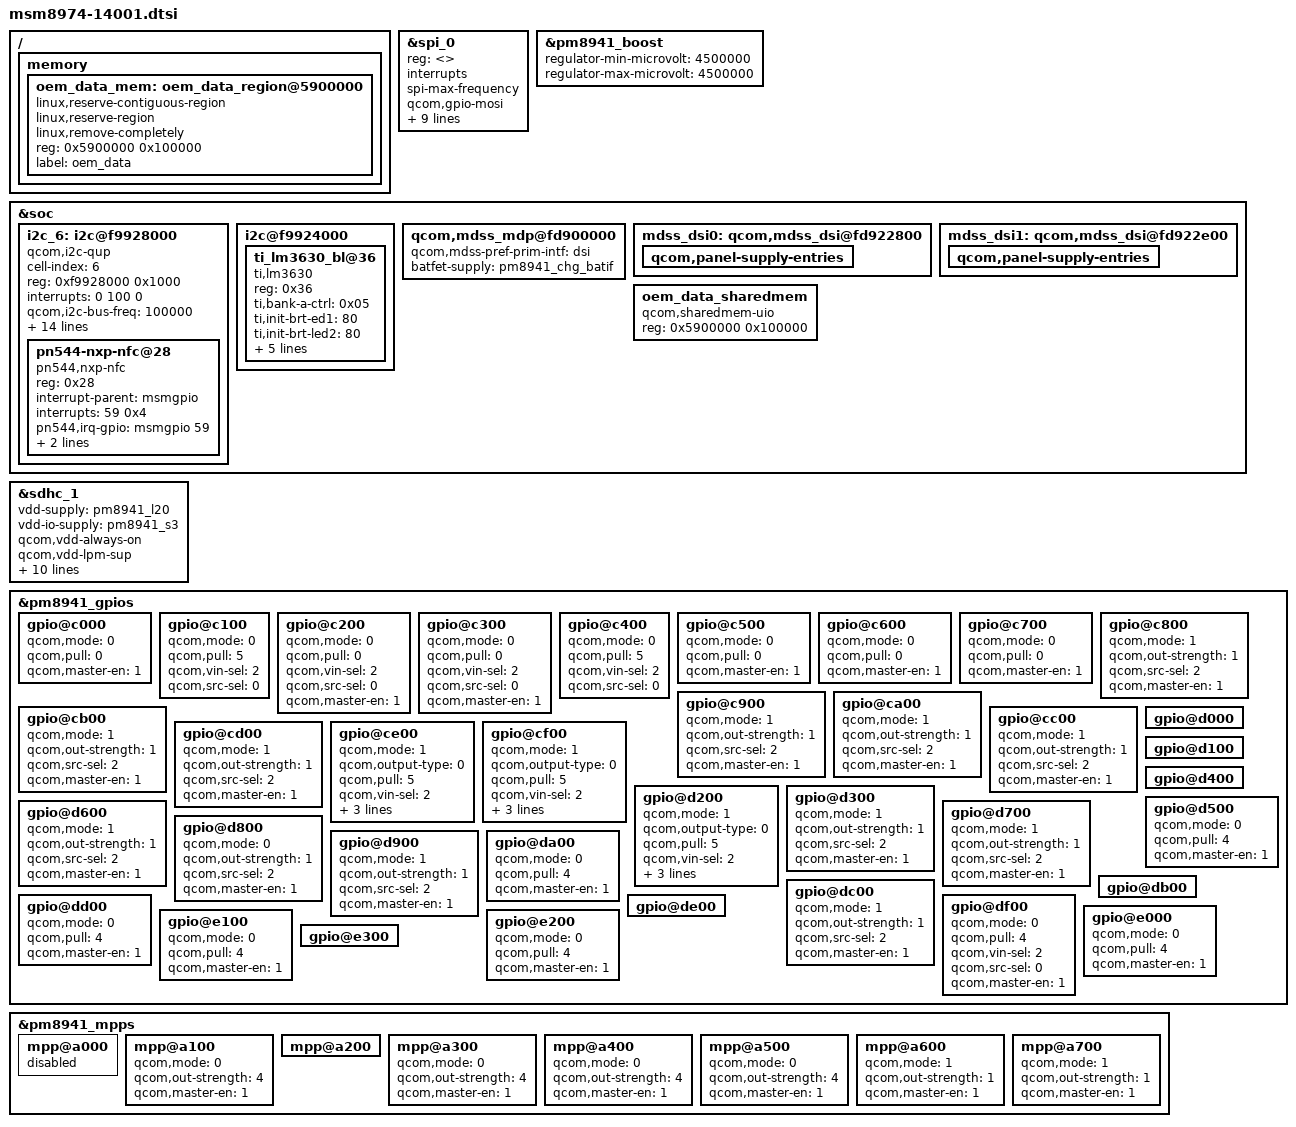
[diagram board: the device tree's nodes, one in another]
/* Copyright (c) 2012-2013, The Linux Foundation. All rights reserved.
 *
 * This program is free software; you can redistribute it and/or modify
 * it under the terms of the GNU General Public License version 2 and
 * only version 2 as published by the Free Software Foundation.
 *
 * This program is distributed in the hope that it will be useful,
 * but WITHOUT ANY WARRANTY; without even the implied warranty of
 * MERCHANTABILITY or FITNESS FOR A PARTICULAR PURPOSE.  See the
 * GNU General Public License for more details.
 */

#include "dsi-panel-jdi-1080p-cmd.dtsi"
#include "../../qcom/msm8974-leds.dtsi"
#include "msm8974-14001-camera.dtsi"
#include "msm8974-oppo-input.dtsi"
#include "msm8974-oppo-pm.dtsi"
#include "msm8974-oppo-regulator.dtsi"

/ {
	memory {
		oem_data_mem: oem_data_region@5900000 {
			linux,reserve-contiguous-region;
			linux,reserve-region;
			linux,remove-completely;
			reg = <0x5900000 0x100000>;
			label = "oem_data";
		};
	};
};

&spi_0 {
	compatible;
	reg-names;
	reg = <>;
	interrupt-names;
	interrupts;
	spi-max-frequency;
	qcom,gpio-mosi;
	qcom,gpio-miso;
	qcom,gpio-clk;
	qcom,gpio-cs0;
	qcom,infinite-mode;
	qcom,use-bam;
	qcom,ver-reg-exists;
	qcom,bam-consumer-pipe-index;
	qcom,bam-producer-pipe-index;
	qcom,master-id;
};

&pm8941_boost {
	regulator-min-microvolt = <4500000>;
	regulator-max-microvolt = <4500000>;
};

&soc {
	i2c_6: i2c@f9928000 {
		cell-index = <6>;
		compatible = "qcom,i2c-qup";
		reg = <0xf9928000 0x1000>;
		#address-cells = <1>;
		#size-cells = <0>;
		reg-names = "qup_phys_addr";
		interrupts = <0 100 0>;
		interrupt-names = "qup_err_intr";
		qcom,i2c-bus-freq = <100000>;
		qcom,i2c-src-freq = <19200000>;
		qcom,scl-gpio = <&msmgpio 30 0>;
		qcom,sda-gpio = <&msmgpio 29 0>;
		qcom,active-only;
		qcom,master-id = <86>;

		qcom,gpio-mosi = <&msmgpio 0 0>;
		qcom,gpio-miso = <&msmgpio 1 0>;
		qcom,gpio-clk  = <&msmgpio 3 0>;
		qcom,gpio-cs2  = <&msmgpio 9 0>;

		qcom,infinite-mode = <0>;
		qcom,use-bam;
		qcom,ver-reg-exists;
		qcom,bam-consumer-pipe-index = <12>;
		qcom,bam-producer-pipe-index = <13>;
		qcom,master-id = <86>;

		pn544-nxp-nfc@28 {
			compatible = "pn544,nxp-nfc";
			reg = <0x28>;
			interrupt-parent = <&msmgpio>;
			interrupts = <59 0x4>;
			pn544,irq-gpio = <&msmgpio 59 0x00>;
			pn544,enable-gpio = <&msmgpio 13 0x00>;
			pn544,update-gpio = <&msmgpio 12 0x00>;
		};
	};

	i2c@f9924000 {
		ti_lm3630_bl@36 {
			compatible = "ti,lm3630";
			reg = <0x36>;
			ti,bank-a-ctrl = <0x05>;
			ti,init-brt-ed1 = <80>;
			ti,init-brt-led2 = <80>;
			ti,max-brt-led1 = <255>;
			ti,max-brt-led2 = <255>;
			ti,pwm-active = <0>;
			ti,pwm-ctrl = <0>;
			ti,pwm-period = <255>;
		};
	};

	qcom,mdss_mdp@fd900000 {
		qcom,mdss-pref-prim-intf = "dsi";
		batfet-supply = <&pm8941_chg_batif>;
	};

	mdss_dsi0: qcom,mdss_dsi@fd922800 {
		qcom,panel-supply-entries {
			/delete-property/ qcom,panel-supply-entry@0;
		};
	};

	mdss_dsi1: qcom,mdss_dsi@fd922e00 {
		qcom,panel-supply-entries {
			/delete-property/ qcom,panel-supply-entry@0;
		};
	};

	oem_data_sharedmem {
		compatible = "qcom,sharedmem-uio";
		reg = <0x5900000 0x100000>;
		reg-names = "oem_data";
	};
};

&sdhc_1 {
	vdd-supply = <&pm8941_l20>;
	vdd-io-supply = <&pm8941_s3>;

	qcom,vdd-always-on;
	qcom,vdd-lpm-sup;
	qcom,vdd-voltage-level = <2950000 2950000>;
	qcom,vdd-current-level = <800 500000>;

	qcom,vdd-io-always-on;
	qcom,vdd-io-voltage-level = <1800000 1800000>;
	qcom,vdd-io-current-level = <250 154000>;

	pinctrl-names = "active", "sleep";
	pinctrl-0 = <&sdc1_clk_on &sdc1_cmd_on &sdc1_data_on>;
	pinctrl-1 = <&sdc1_clk_off &sdc1_cmd_off &sdc1_data_off>;

	qcom,nonremovable;
	status = "ok";
};

&pm8941_gpios {
	gpio@c000 { /* GPIO 1 */
		qcom,mode = <0>;        /* QPNP_PIN_MODE_DIG_IN */
		qcom,pull = <0>;        /* QPNP_PIN_PULL_UP_30  */
		qcom,master-en = <1>;
	};

	gpio@c100 { /* GPIO 2 */
		qcom,mode = <0>;        /* QPNP_PIN_MODE_DIG_IN */
		qcom,pull = <5>;        /* QPNP_PIN_PULL_UP_30  */
		qcom,vin-sel = <2>;
		qcom,src-sel = <0>;
	};

	gpio@c200 { /* GPIO 3 */
		qcom,mode = <0>;        /* QPNP_PIN_MODE_DIG_IN */
		qcom,pull = <0>;        /* QPNP_PIN_PULL_UP_30  */
		qcom,vin-sel = <2>;
		qcom,src-sel = <0>;	/* QPNP_PIN_SEL_FUNC_CONSTANT */
		qcom,master-en = <1>;
	};

	gpio@c300 { /* GPIO 4 */
		qcom,mode = <0>;        /* QPNP_PIN_MODE_DIG_IN */
		qcom,pull = <0>;        /* QPNP_PIN_PULL_UP_30  */
		qcom,vin-sel = <2>;     /* QPNP_PIN_VIN2  */
		qcom,src-sel = <0>;	/* QPNP_PIN_SEL_FUNC_CONSTANT */
		qcom,master-en = <1>;
	};

	gpio@c400 { /* GPIO 5 */
		qcom,mode = <0>;        /* QPNP_PIN_MODE_DIG_IN */
		qcom,pull = <5>;        /* QPNP_PIN_PULL_UP_30  */
		qcom,vin-sel = <2>;     /* QPNP_PIN_VIN2  */
		qcom,src-sel = <0>;	/* QPNP_PIN_SEL_FUNC_CONSTANT */
	};

	gpio@c500 { /* GPIO 6 */
		qcom,mode = <0>;        /* QPNP_PIN_MODE_DIG_IN */
		qcom,pull = <0>;        /* QPNP_PIN_PULL_UP_30  */
		qcom,master-en = <1>;
	};

	gpio@c600 { /* GPIO 7 */
		qcom,mode = <0>;        /* QPNP_PIN_MODE_DIG_IN */
		qcom,pull = <0>;        /* QPNP_PIN_PULL_UP_30  */
		qcom,master-en = <1>;
	};

	gpio@c700 { /* GPIO 8 */
		qcom,mode = <0>;        /* QPNP_PIN_MODE_DIG_IN */
		qcom,pull = <0>;        /* QPNP_PIN_PULL_UP_30  */
		qcom,master-en = <1>;
	};

	gpio@c800 { /* GPIO 9 */
		qcom,mode = <1>;          /* QPNP_PIN_MODE_DIG_OUT */
		qcom,out-strength = <1>;  /* QPNP_PIN_OUT_STRENGTH_LOW */
		qcom,src-sel = <2>;       /* QPNP_PIN_SEL_FUNC_1  */
		qcom,master-en = <1>;
	};

	gpio@c900 { /* GPIO 10 */
		qcom,mode = <1>;          /* QPNP_PIN_MODE_DIG_OUT */
		qcom,out-strength = <1>;  /* QPNP_PIN_OUT_STRENGTH_LOW */
		qcom,src-sel = <2>;       /* QPNP_PIN_SEL_FUNC_1  */
		qcom,master-en = <1>;
	};

	gpio@ca00 { /* GPIO 11 */
		qcom,mode = <1>;          /* QPNP_PIN_MODE_DIG_OUT */
		qcom,out-strength = <1>;  /* QPNP_PIN_OUT_STRENGTH_LOW */
		qcom,src-sel = <2>;       /* QPNP_PIN_SEL_FUNC_1  */
		qcom,master-en = <1>;
	};

	gpio@cb00 { /* GPIO 12 */
		qcom,mode = <1>;          /* QPNP_PIN_MODE_DIG_OUT */
		qcom,out-strength = <1>;  /* QPNP_PIN_OUT_STRENGTH_LOW */
		qcom,src-sel = <2>;       /* QPNP_PIN_SEL_FUNC_1  */
		qcom,master-en = <1>;
	};

	gpio@cc00 { /* GPIO 13 */
		qcom,mode = <1>;          /* QPNP_PIN_MODE_DIG_OUT */
		qcom,out-strength = <1>;  /* QPNP_PIN_OUT_STRENGTH_LOW */
		qcom,src-sel = <2>;       /* QPNP_PIN_SEL_FUNC_1  */
		qcom,master-en = <1>;
	};

	gpio@cd00 { /* GPIO 14 */
		qcom,mode = <1>;          /* QPNP_PIN_MODE_DIG_OUT */
		qcom,out-strength = <1>;  /* QPNP_PIN_OUT_STRENGTH_LOW */
		qcom,src-sel = <2>;       /* QPNP_PIN_SEL_FUNC_1  */
		qcom,master-en = <1>;
	};

	gpio@ce00 { /* GPIO 15 */
		qcom,mode = <1>;
		qcom,output-type = <0>;
		qcom,pull = <5>;
		qcom,vin-sel = <2>;
		qcom,out-strength = <1>;
		qcom,src-sel = <2>;
		qcom,master-en = <1>;
	};

	gpio@cf00 { /* GPIO 16 */
		qcom,mode = <1>;
		qcom,output-type = <0>;
		qcom,pull = <5>;
		qcom,vin-sel = <2>;
		qcom,out-strength = <1>;
		qcom,src-sel = <2>;       /* QPNP_PIN_SEL_FUNC_2  */
		qcom,master-en = <1>;
	};

	gpio@d000 { /* GPIO 17 */
	};

	gpio@d100 { /* GPIO 18 */
	};

	gpio@d200 { /* GPIO 19 */
		qcom,mode = <1>;		/* QPNP_PIN_MODE_DIG_OUT */
		qcom,output-type = <0>;		/* QPNP_PIN_OUT_BUF_CMOS */
		qcom,pull = <5>;		/* QPNP_PIN_PULL_NO */
		qcom,vin-sel = <2>;		/* QPNP_PIN_VIN2 */
		qcom,out-strength = <1>;	/* QPNP_PIN_OUT_STRENGTH_LOW */
		qcom,src-sel = <0>;		/* QPNP_PIN_SEL_FUNC_CONSTANT */
		qcom,master-en = <1>;
	};

	gpio@d300 { /* GPIO 20 */
		qcom,mode = <1>;          /* QPNP_PIN_MODE_DIG_OUT */
		qcom,out-strength = <1>;  /* QPNP_PIN_OUT_STRENGTH_LOW */
		qcom,src-sel = <2>;       /* QPNP_PIN_SEL_FUNC_1  */
		qcom,master-en = <1>;
	};

	gpio@d400 { /* GPIO 21 */
	};

	gpio@d500 { /* GPIO 22 */
		qcom,mode = <0>;        /* QPNP_PIN_MODE_DIG_IN */
		qcom,pull = <4>;	/* QPNP_PIN_PULL_DN */
		qcom,master-en = <1>;
	};

	gpio@d600 { /* GPIO 23 */
		qcom,mode = <1>;          /* QPNP_PIN_MODE_DIG_OUT */
		qcom,out-strength = <1>;  /* QPNP_PIN_OUT_STRENGTH_LOW */
		qcom,src-sel = <2>;       /* QPNP_PIN_SEL_FUNC_1  */
		qcom,master-en = <1>;
	};

	gpio@d700 { /* GPIO 24 */
		qcom,mode = <1>;          /* QPNP_PIN_MODE_DIG_OUT */
		qcom,out-strength = <1>;  /* QPNP_PIN_OUT_STRENGTH_LOW */
		qcom,src-sel = <2>;       /* QPNP_PIN_SEL_FUNC_1  */
		qcom,master-en = <1>;
	};

	gpio@d800 { /* GPIO 25 */
		qcom,mode = <0>;          /* QPNP_PIN_MODE_DIG_OUT */
		qcom,out-strength = <1>;  /* QPNP_PIN_OUT_STRENGTH_LOW */
		qcom,src-sel = <2>;       /* QPNP_PIN_SEL_FUNC_1  */
		qcom,master-en = <1>;
	};

	gpio@d900 { /* GPIO 26 */
		qcom,mode = <1>;          /* QPNP_PIN_MODE_DIG_OUT */
		qcom,out-strength = <1>;  /* QPNP_PIN_OUT_STRENGTH_LOW */
		qcom,src-sel = <2>;       /* QPNP_PIN_SEL_FUNC_1  */
		qcom,master-en = <1>;
	};

	gpio@da00 { /* GPIO 27 */
		qcom,mode = <0>;        /* QPNP_PIN_MODE_DIG_IN */
		qcom,pull = <4>;	/* QPNP_PIN_PULL_DN */
		qcom,master-en = <1>;
	};

	gpio@db00 { /* GPIO 28 */
	};

	gpio@dc00 { /* GPIO 29 */
		qcom,mode = <1>;          /* QPNP_PIN_MODE_DIG_OUT */
		qcom,out-strength = <1>;  /* QPNP_PIN_OUT_STRENGTH_LOW */
		qcom,src-sel = <2>;       /* QPNP_PIN_SEL_FUNC_1  */
		qcom,master-en = <1>;
	};

	gpio@dd00 { /* GPIO 30 */
		qcom,mode = <0>;        /* QPNP_PIN_MODE_DIG_IN */
		qcom,pull = <4>;	/* QPNP_PIN_PULL_DN */
		qcom,master-en = <1>;
	};

	gpio@de00 { /* GPIO 31 */
	};

	gpio@df00 { /* GPIO 32 */
		qcom,mode = <0>;        /* QPNP_PIN_MODE_DIG_IN */
		qcom,pull = <4>;	/* QPNP_PIN_PULL_DN */
		qcom,vin-sel = <2>;
		qcom,src-sel = <0>;	/* QPNP_PIN_SEL_FUNC_CONSTANT */
		qcom,master-en = <1>;
	};

	gpio@e000 { /* GPIO 33 */
		qcom,mode = <0>;        /* QPNP_PIN_MODE_DIG_IN */
		qcom,pull = <4>;	/* QPNP_PIN_PULL_DN */
		qcom,master-en = <1>;
	};

	gpio@e100 { /* GPIO 34 */
		qcom,mode = <0>;        /* QPNP_PIN_MODE_DIG_IN */
		qcom,pull = <4>;	/* QPNP_PIN_PULL_DN */
		qcom,master-en = <1>;
	};

	gpio@e200 { /* GPIO 35 */
		qcom,mode = <0>;        /* QPNP_PIN_MODE_DIG_IN */
		qcom,pull = <4>;	/* QPNP_PIN_PULL_DN */
		qcom,master-en = <1>;
	};

	gpio@e300 { /* GPIO 36 */
	};
};

&pm8941_mpps {

	mpp@a000 { /* MPP 1 */
		status = "disabled";
	};

	mpp@a100 { /* MPP 2 */
		qcom,mode = <0>;          /* QPNP_PIN_MODE_DIG_IN */
		qcom,out-strength = <4>;  /* QPNP_PIN_PULL_DN */
		qcom,master-en = <1>;
	};

	mpp@a200 { /* MPP 3 */
	};

	mpp@a300 { /* MPP 4 */
		qcom,mode = <0>;          /* QPNP_PIN_MODE_DIG_IN */
		qcom,out-strength = <4>;  /* QPNP_PIN_PULL_DN */
		qcom,master-en = <1>;
	};

	mpp@a400 { /* MPP 5 */
		qcom,mode = <0>;          /* QPNP_PIN_MODE_DIG_IN */
		qcom,out-strength = <4>;  /* QPNP_PIN_PULL_DN */
		qcom,master-en = <1>;
	};

	mpp@a500 { /* MPP 6 */
		qcom,mode = <0>;          /* QPNP_PIN_MODE_DIG_IN */
		qcom,out-strength = <4>;  /* QPNP_PIN_PULL_DN */
		qcom,master-en = <1>;
	};

	mpp@a600 { /* MPP 7 */
		qcom,mode = <1>;          /* QPNP_PIN_MODE_DIG_OUT */
		qcom,out-strength = <1>;  /* QPNP_PIN_OUT_STRENGTH_LOW */
		qcom,master-en = <1>;
	};

	mpp@a700 { /* MPP 8 */
		qcom,mode = <1>;          /* QPNP_PIN_MODE_DIG_OUT */
		qcom,out-strength = <1>;  /* QPNP_PIN_OUT_STRENGTH_LOW */
		qcom,master-en = <1>;
	};
};
